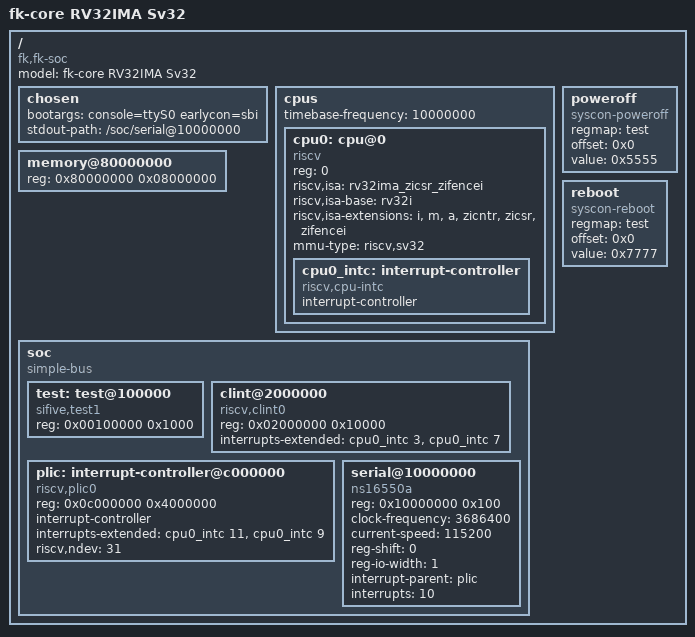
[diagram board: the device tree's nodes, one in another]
/dts-v1/;

/ {
	#address-cells = <1>;
	#size-cells = <1>;
	compatible = "fk,fk-soc";
	model = "fk-core RV32IMA Sv32";

	chosen {
		bootargs = "console=ttyS0 earlycon=sbi";
		stdout-path = "/soc/serial@10000000";
	};

	cpus {
		#address-cells = <1>;
		#size-cells = <0>;
		timebase-frequency = <10000000>;

		cpu0: cpu@0 {
			device_type = "cpu";
			reg = <0>;
			status = "okay";
			compatible = "riscv";
			riscv,isa = "rv32ima_zicsr_zifencei";
			riscv,isa-base = "rv32i";
			riscv,isa-extensions = "i", "m", "a", "zicntr", "zicsr", "zifencei";
			mmu-type = "riscv,sv32";

			cpu0_intc: interrupt-controller {
				#interrupt-cells = <1>;
				compatible = "riscv,cpu-intc";
				interrupt-controller;
			};
		};
	};

	memory@80000000 {
		device_type = "memory";
		reg = <0x80000000 0x08000000>;
	};

	/* power-off / reboot through the test finisher (newer OpenSBI, e.g. v1.5) */
	poweroff {
		compatible = "syscon-poweroff";
		regmap = <&test>;
		offset = <0x0>;
		value = <0x5555>;
	};

	reboot {
		compatible = "syscon-reboot";
		regmap = <&test>;
		offset = <0x0>;
		value = <0x7777>;
	};

	soc {
		#address-cells = <1>;
		#size-cells = <1>;
		compatible = "simple-bus";
		ranges;

		test: test@100000 {
			compatible = "sifive,test1", "sifive,test0", "syscon";
			reg = <0x00100000 0x1000>;
		};

		clint@2000000 {
			compatible = "riscv,clint0";
			reg = <0x02000000 0x10000>;
			interrupts-extended = <&cpu0_intc 3>, <&cpu0_intc 7>;
		};

		plic: interrupt-controller@c000000 {
			compatible = "riscv,plic0";
			reg = <0x0c000000 0x4000000>;
			#address-cells = <0>;
			#interrupt-cells = <1>;
			interrupt-controller;
			interrupts-extended = <&cpu0_intc 11>, <&cpu0_intc 9>;
			riscv,ndev = <31>;
		};

		serial@10000000 {
			compatible = "ns16550a";
			reg = <0x10000000 0x100>;
			clock-frequency = <3686400>;
			current-speed = <115200>;
			reg-shift = <0>;
			reg-io-width = <1>;
			interrupt-parent = <&plic>;
			interrupts = <10>;
		};
	};
};
